# PAC55XX register map
Vendor: Active-Semi; Series: PAC55XX; File version: 1.0
CPU: CM4 r0p1, little endian, MPU, FPU, vendor SysTick, 3 interrupt priority bits
Registers are 32-bit, read-write, reset 0x0 unless marked. A register's access mark holds for its fields unless they carry their own. Offsets are from the block's base; [hi:lo] are bit positions; {n}, {i} and the like mark numbered series.

## USARTA
Base 0x40020000
0x00 RBR_CON — UART A Receive Buffer / SSP A Control
0x04 THR_STAT — UART A Transmit Holding / SSP A Status
0x08 DRL_DAT — UART A Divisor Latch / SSP A Data
0x0C IER_CLK — UART A Interrupt Enable / SSP A Clock Control
0x10 IIR_IMSC — UART A Interrupt Identification / SSP A Interrupt Mask Set and Clear
0x14 FCR_RIS — UART A FIFO Control / SSP A Raw Interrupt Status
0x18 LCR_MIS — UART A Line Control / SSP A Masked Interrupt Status
0x1C ICLR — SSP A Interrupt Clear
0x20 LSR — UART A Line Status
0x28 SCR_SSCR — UART A Scratch Pad / SSP A Slave Select Configuration
0x2C EFR — Enhanced Feature

## USARTB
Base 0x40030000
0x00 RBR_CON — UART B Receive Buffer / SSP B Control
0x04 THR_STAT — UART B Transmit Holding / SSP B Status
0x08 DRL_DAT — UART B Divisor Latch / SSP B Data
0x0C IER_CLK — UART B Interrupt Enable / SSP B Clock Control
0x10 IIR_IMSC — UART B Interrupt Identification / SSP B Interrupt Mask Set and Clear
0x14 FCR_RIS — UART B FIFO Control / SSP B Raw Interrupt Status
0x18 LCR_MIS — UART B Line Control / SSP B Masked Interrupt Status
0x1C ICLR — SSP B Interrupt Clear
0x20 LSR — UART B Line Status
0x28 SCR_SSCR — UART B Scratch Pad / SSP B Slave Select Configuration
0x2C EFR — Enhanced Feature

## USARTC
Base 0x40040000
0x00 RBR_CON — UART C Receive Buffer / SSP C Control
0x04 THR_STAT — UART C Transmit Holding / SSP C Status
0x08 DRL_DAT — UART C Divisor Latch / SSP C Data
0x0C IER_CLK — UART C Interrupt Enable / SSP C Clock Control
0x10 IIR_IMSC — UART C Interrupt Identification / SSP C Interrupt Mask Set and Clear
0x14 FCR_RIS — UART C FIFO Control / SSP C Raw Interrupt Status
0x18 LCR_MIS — UART C Line Control / SSP C Masked Interrupt Status
0x1C ICLR — SSP C Interrupt Clear
0x20 LSR — UART C Line Status
0x28 SCR_SSCR — UART C Scratch Pad / SSP C Slave Select Configuration
0x2C EFR — Enhanced Feature

## USARTD
Base 0x40050000
0x00 RBR_CON — UART D Receive Buffer / SSP D Control
0x04 THR_STAT — UART D Transmit Holding / SSP D Status
0x08 DRL_DAT — UART D Divisor Latch / SSP D Data
0x0C IER_CLK — UART D Interrupt Enable / SSP D Clock Control
0x10 IIR_IMSC — UART D Interrupt Identification / SSP D Interrupt Mask Set and Clear
0x14 FCR_RIS — UART D FIFO Control / SSP D Raw Interrupt Status
0x18 LCR_MIS — UART D Line Control / SSP D Masked Interrupt Status
0x1C ICLR — SSP D Interrupt Clear
0x20 LSR — UART D Line Status
0x28 SCR_SSCR — UART D Scratch Pad / SSP D Slave Select Configuration
0x2C EFR — Enhanced Feature

## TimerA
Base 0x40060000
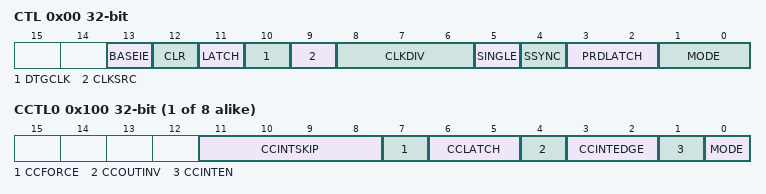
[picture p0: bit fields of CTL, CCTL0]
0x00 CTL — Timer A Control
  [13] BASEIE — Base timer interrupt enable
    0=Disabled (Base interrupt disabled); 1=Enabled (Base interrupt enabled)
  [12] CLR — Timer Clear
    0=Do not clear timer counter; 1=Clear timer counter
  [11] LATCH — Write 1 to Latch Period and all CCTRs
  [10] DTGCLK — Dead-Time Generator Clock Source
    0=Before Divider (Before input clock divider); 1=After Divider (After input clock divider)
  [9] CLKSRC — Timer Clock Source
    0=PCLK (PCLK selected as input to timer); 1=ACLK (ACLK selected as input to timer)
  [8:6] CLKDIV — Timer Input Clock Divider
    0=/1 (Timer input clock /1); 1=/2 (Timer input clock /2); 2=/4 (Timer input clock /4); 3=/8 (Timer input clock /8); 4=/16 (Timer input clock /16); 5=/32 (Timer input clock /32); 6=/64 (Timer input clock /64); 7=/128 (Timer input clock /128)
  [5] SINGLE — Single Shot Timer
    0=Disabled (Single Shot Disabled (auto-reload)); 1=Enabled (Single Shot Timer Enabled)
  [4] SSYNC — Timer Slave Synchronization
    0=Disabled (Slave Sync Disabled); 1=Enabled (Slave Sync Enabled)
  [3:2] PRDLATCH — Timer Period Latch Mode
    0=CTR=0 (Period is latched when CTR = 0); 1=CTR=Period (Period is latched when CTR = Period); 2=Immediate (Period is latched immediately upon register write)
  [1:0] MODE — Timer Mode
    0=Disabled Mode; 1=Up (Up Mode); 2=Up/Down Mode; 3=Asymmetric Mode
0x04 INT — Timer A Interrupt Control
0x08 PRD — Timer A Period
0x0C CTR — Timer A Counter
0x10 QEPCTL — Timer A QEP Control
{0x100+8i} CCTL{i} (i=0..7) — Timer A CC Control {i}
  [11:8] CCINTSKIP — CC Interrupt Skip Counter
    0=Don't skip CCR matches before interrupt; 1=Skip 1 CCR match before interrupt; {v}=Skip {v} CCR matches before interrupt (v=2..15)
  [7] CCFORCE — Write 1 to force compare event (self-clearing)
  [6:5] CCLATCH — CCR Register Latch Mode
    0=CTR=0/Rising (Compare(latch on CTR=0)/ Capture(latch on rising edge)); 1=CTR=Period/Falling (Compare(latch on CTR=Period)/ Capture(latch on falling edge)); 2=Immediate/Both (Compare(latch immediately)/ Capture(latch on both edges))
  [4] CCOUTINV — Invert CCR Output
    0=Not Inverted (Do not invert CCR output); 1=Inverted (Invert CCR output)
  [3:2] CCINTEDGE — Capture Mode Interrupt Edge Setting
    0=Rising Edge Interrupt; 1=Falling Edge Interrupt; 2=Both (Rising and Falling Edge Interrupt)
  [1] CCINTEN — CCR Interrupt Enable
    0=Disabled (CCR interrupt disabled); 1=Enabled (CCR interrupt enabled)
  [0] MODE — CCR Mode
    0=Compare Mode; 1=Capture Mode
{0x104+8i} CCTR{i} (i=0..7) — Timer A CC Counter {i}
{0x200+4i} DTGCTL{i} (i=0..3) — Timer A DTG Control {i}
